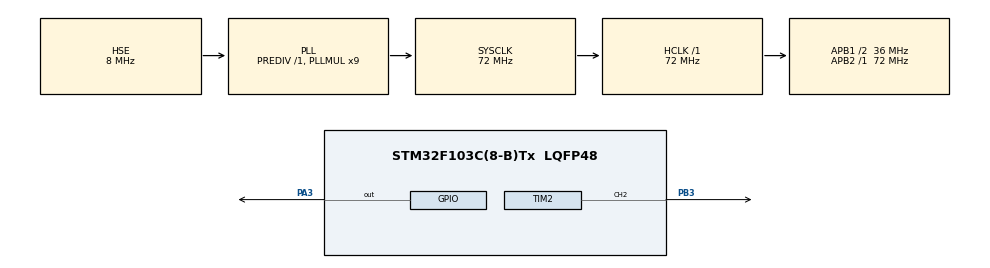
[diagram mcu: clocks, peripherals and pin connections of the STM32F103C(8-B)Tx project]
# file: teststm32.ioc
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Dma.Request0=TIM2_CH2/CH4
Dma.TIM2_CH2/CH4.0.Direction=DMA_MEMORY_TO_PERIPH
Dma.TIM2_CH2/CH4.0.Instance=DMA1_Channel7
Dma.TIM2_CH2/CH4.0.MemDataAlignment=DMA_MDATAALIGN_HALFWORD
Dma.TIM2_CH2/CH4.0.MemInc=DMA_MINC_ENABLE
Dma.TIM2_CH2/CH4.0.Mode=DMA_NORMAL
Dma.TIM2_CH2/CH4.0.PeriphDataAlignment=DMA_PDATAALIGN_HALFWORD
Dma.TIM2_CH2/CH4.0.PeriphInc=DMA_PINC_DISABLE
Dma.TIM2_CH2/CH4.0.Priority=DMA_PRIORITY_LOW
Mcu.Family=STM32F1
Mcu.Name=STM32F103C(8-B)Tx
Mcu.Package=LQFP48
NVIC.DMA1_Channel7_IRQn=true\:0\:0\:false\:false\:true\:false\:true\:true
NVIC.PriorityGroup=NVIC_PRIORITYGROUP_4
NVIC.TIM2_IRQn=true\:0\:0\:false\:false\:true\:true\:true\:true
PA3.GPIO_ModeDefaultOutputPP=GPIO_MODE_OUTPUT_OD
PA3.GPIO_PuPd=GPIO_NOPULL
PA3.Signal=GPIO_Output
PB3.Signal=S_TIM2_CH2
PD0-OSC_IN.Mode=HSE-External-Oscillator
PD0-OSC_IN.Signal=RCC_OSC_IN
PD1-OSC_OUT.Mode=HSE-External-Oscillator
PD1-OSC_OUT.Signal=RCC_OSC_OUT
ProjectManager.HeapSize=0x200
ProjectManager.StackSize=0x400
ProjectManager.TargetToolchain=STM32CubeIDE
RCC.AHBFreq_Value=72000000
RCC.APB1CLKDivider=RCC_HCLK_DIV2
RCC.APB1Freq_Value=36000000
RCC.APB1TimFreq_Value=72000000
RCC.APB2Freq_Value=72000000
RCC.APB2TimFreq_Value=72000000
RCC.HCLKFreq_Value=72000000
RCC.PLLMUL=RCC_PLL_MUL9
RCC.PLLSourceVirtual=RCC_PLLSOURCE_HSE
RCC.SYSCLKFreq_VALUE=72000000
RCC.SYSCLKSource=RCC_SYSCLKSOURCE_PLLCLK
RCC.USBFreq_Value=72000000
SH.S_TIM2_CH2.0=TIM2_CH2,PWM Generation2 CH2
TIM2.Channel-PWM\ Generation2\ CH2=TIM_CHANNEL_2
TIM2.Period=89
TIM2.Pulse-PWM\ Generation2\ CH2=59
VP_SYS_VS_ND.Mode=No_Debug
board=custom

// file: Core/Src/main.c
/* USER CODE BEGIN Header */
/**
  ******************************************************************************
  * @file           : main.c
  * @brief          : Main program body
  ******************************************************************************
  * @attention
  *
  * Copyright (c) 2023 STMicroelectronics.
  * All rights reserved.
  *
  * This software is licensed under terms that can be found in the LICENSE file
  * in the root directory of this software component.
  * If no LICENSE file comes with this software, it is provided AS-IS.
  *
  ******************************************************************************
  */
/* USER CODE END Header */
#include "main.h"

/* USER CODE BEGIN Includes */
#include "ws2812b.h"
/* USER CODE END Includes */

TIM_HandleTypeDef htim2;
DMA_HandleTypeDef hdma_tim2_ch2_ch4;

void SystemClock_Config(void);
static void MX_GPIO_Init(void);
static void MX_DMA_Init(void);
static void MX_TIM2_Init(void);

int main(void)
{

  /* MCU Configuration--------------------------------------------------------*/

  /* Reset of all peripherals, Initializes the Flash interface and the Systick. */
  HAL_Init();

  /* Configure the system clock */
  SystemClock_Config();

  /* Initialize all configured peripherals */
  MX_GPIO_Init();
  MX_DMA_Init();
  MX_TIM2_Init();
  /* USER CODE BEGIN 2 */
  initWS2812b(GPIOB, GPIO_PIN_3, &htim2, TIM_CHANNEL_2);
  /* USER CODE END 2 */

  /* Infinite loop */
  /* USER CODE BEGIN WHILE */
  uint16_t buf1[] = {
		  59,59,59,59,59,59,59,59,
		  29,29,29,29,29,29,29,29,
		  59,59,59,59,59,59,59,59,

		  59,59,59,59,59,59,59,59,
		  29,29,29,29,29,29,29,29,
		  29,29,29,29,29,29,29,29,
  };
  uint16_t buf2[] = {
		  59,59,59,59,59,59,59,59,
		  29,29,29,29,29,29,29,29,
		  29,29,29,29,29,29,29,29,

  		  59,59,59,59,59,59,59,59,
  		  29,29,29,29,29,29,29,29,
  		  59,59,59,59,59,59,59,59,
    };
  static int k = 0;
  while (1)
  {
    /* USER CODE END WHILE */

    /* USER CODE BEGIN 3 */
	 if (k == 0){
		 startOutput(buf1, sizeof(buf1) / sizeof(buf1[0]));
		 k = 1;
	 }else{
		 startOutput(buf2, sizeof(buf2) / sizeof(buf2[0]));
		 k = 0;
	 }
	 HAL_Delay(1000);
  }
  /* USER CODE END 3 */
}

void SystemClock_Config(void)
{
  RCC_OscInitTypeDef RCC_OscInitStruct = {0};
  RCC_ClkInitTypeDef RCC_ClkInitStruct = {0};

  /** Initializes the RCC Oscillators according to the specified parameters
  * in the RCC_OscInitTypeDef structure.
  */
  RCC_OscInitStruct.OscillatorType = RCC_OSCILLATORTYPE_HSE;
  RCC_OscInitStruct.HSEState = RCC_HSE_ON;
  RCC_OscInitStruct.HSEPredivValue = RCC_HSE_PREDIV_DIV1;
  RCC_OscInitStruct.HSIState = RCC_HSI_ON;
  RCC_OscInitStruct.PLL.PLLState = RCC_PLL_ON;
  RCC_OscInitStruct.PLL.PLLSource = RCC_PLLSOURCE_HSE;
  RCC_OscInitStruct.PLL.PLLMUL = RCC_PLL_MUL9;
  if (HAL_RCC_OscConfig(&RCC_OscInitStruct) != HAL_OK)
  {
    Error_Handler();
  }

  /** Initializes the CPU, AHB and APB buses clocks
  */
  RCC_ClkInitStruct.ClockType = RCC_CLOCKTYPE_HCLK|RCC_CLOCKTYPE_SYSCLK
                              |RCC_CLOCKTYPE_PCLK1|RCC_CLOCKTYPE_PCLK2;
  RCC_ClkInitStruct.SYSCLKSource = RCC_SYSCLKSOURCE_PLLCLK;
  RCC_ClkInitStruct.AHBCLKDivider = RCC_SYSCLK_DIV1;
  RCC_ClkInitStruct.APB1CLKDivider = RCC_HCLK_DIV2;
  RCC_ClkInitStruct.APB2CLKDivider = RCC_HCLK_DIV1;

  if (HAL_RCC_ClockConfig(&RCC_ClkInitStruct, FLASH_LATENCY_2) != HAL_OK)
  {
    Error_Handler();
  }
}

static void MX_TIM2_Init(void)
{

  TIM_MasterConfigTypeDef sMasterConfig = {0};
  TIM_OC_InitTypeDef sConfigOC = {0};

  htim2.Instance = TIM2;
  htim2.Init.Prescaler = 0;
  htim2.Init.CounterMode = TIM_COUNTERMODE_UP;
  htim2.Init.Period = 89;
  htim2.Init.ClockDivision = TIM_CLOCKDIVISION_DIV1;
  htim2.Init.AutoReloadPreload = TIM_AUTORELOAD_PRELOAD_DISABLE;
  if (HAL_TIM_PWM_Init(&htim2) != HAL_OK)
  {
    Error_Handler();
  }
  sMasterConfig.MasterOutputTrigger = TIM_TRGO_RESET;
  sMasterConfig.MasterSlaveMode = TIM_MASTERSLAVEMODE_DISABLE;
  if (HAL_TIMEx_MasterConfigSynchronization(&htim2, &sMasterConfig) != HAL_OK)
  {
    Error_Handler();
  }
  sConfigOC.OCMode = TIM_OCMODE_PWM1;
  sConfigOC.Pulse = 59;
  sConfigOC.OCPolarity = TIM_OCPOLARITY_HIGH;
  sConfigOC.OCFastMode = TIM_OCFAST_DISABLE;
  if (HAL_TIM_PWM_ConfigChannel(&htim2, &sConfigOC, TIM_CHANNEL_2) != HAL_OK)
  {
    Error_Handler();
  }
  HAL_TIM_MspPostInit(&htim2);

}

static void MX_DMA_Init(void)
{

  /* DMA controller clock enable */
  __HAL_RCC_DMA1_CLK_ENABLE();

  /* DMA interrupt init */
  /* DMA1_Channel7_IRQn interrupt configuration */
  HAL_NVIC_SetPriority(DMA1_Channel7_IRQn, 0, 0);
  HAL_NVIC_EnableIRQ(DMA1_Channel7_IRQn);

}

static void MX_GPIO_Init(void)
{
  GPIO_InitTypeDef GPIO_InitStruct = {0};

  /* GPIO Ports Clock Enable */
  __HAL_RCC_GPIOD_CLK_ENABLE();
  __HAL_RCC_GPIOA_CLK_ENABLE();
  __HAL_RCC_GPIOB_CLK_ENABLE();

  /*Configure GPIO pin Output Level */
  HAL_GPIO_WritePin(GPIOA, GPIO_PIN_3, GPIO_PIN_RESET);

  /*Configure GPIO pin : PA3 */
  GPIO_InitStruct.Pin = GPIO_PIN_3;
  GPIO_InitStruct.Mode = GPIO_MODE_OUTPUT_OD;
  GPIO_InitStruct.Pull = GPIO_NOPULL;
  GPIO_InitStruct.Speed = GPIO_SPEED_FREQ_LOW;
  HAL_GPIO_Init(GPIOA, &GPIO_InitStruct);

}

void Error_Handler(void)
{
  __disable_irq();
  while (1)
  {
  }
}
